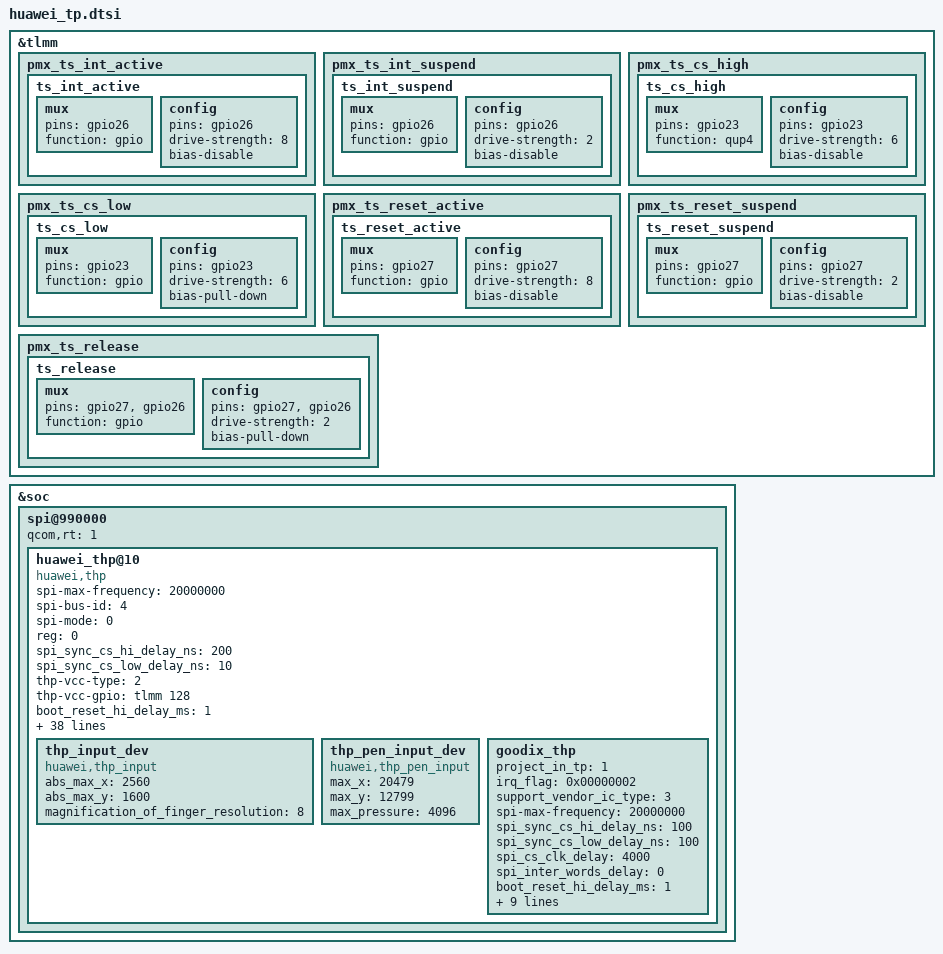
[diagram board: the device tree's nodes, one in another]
/* touch panel config */
&tlmm {
	pmx_ts_int_active {
		ts_int_active: ts_int_active {
			mux {
				pins = "gpio26";
				function = "gpio";
			};

			config {
				pins = "gpio26";
				drive-strength = <8>;
				bias-disable;
			};
		};
	};

	pmx_ts_int_suspend {
		ts_int_suspend: ts_int_suspend {
			mux {
				pins = "gpio26";
				function = "gpio";
			};

			config {
				pins = "gpio26";
				drive-strength = <2>;
				bias-disable;
			};
		};
	};

	pmx_ts_cs_high {
		ts_cs_high: ts_cs_high {
			mux {
				pins = "gpio23";
				function = "qup4";
			};

			config {
				pins = "gpio23";
				drive-strength = <6>;
				bias-disable;
			};
		};
	};

	pmx_ts_cs_low {
		ts_cs_low: ts_cs_low {
			mux {
				pins = "gpio23";
				function = "gpio";
			};

			config {
				pins = "gpio23";
				drive-strength = <6>;
				bias-pull-down;
			};
		};
	};

	pmx_ts_reset_active {
		ts_reset_active: ts_reset_active {
			mux {
				pins = "gpio27";
				function = "gpio";
			};

			config {
				pins = "gpio27";
				drive-strength = <8>;
				bias-disable;
			};
		};
	};

	pmx_ts_reset_suspend {
		ts_reset_suspend: ts_reset_suspend {
			mux {
				pins = "gpio27";
				function = "gpio";
			};

			config {
				pins = "gpio27";
				drive-strength = <2>;
				bias-disable;
			};
		};
	};

	pmx_ts_release {
		ts_release: ts_release {
			mux {
				pins = "gpio27", "gpio26";
				function = "gpio";
			};

			config {
				pins = "gpio27", "gpio26";
				drive-strength = <2>;
				bias-pull-down;
			};
		};
	};
};

&soc {
	spi@990000 {
		status = "ok";
		#address-cells = <1>;
		#size-cells = <0>;
		qcom,rt = <1>;
		huawei_thp@10 {
			compatible = "huawei,thp";
			status = "ok";
			/* SPI Config */
			spi-max-frequency = <20000000>;
			spi-bus-id = <4>;
			spi-mode = <0>;
			reg = <0>;
			spi_sync_cs_hi_delay_ns = <200>;
			spi_sync_cs_low_delay_ns = <10>;

			/* Power Config */
			thp-vcc-type = <2>;
			thp-vcc-gpio = <&tlmm 128 0>;

			/* Timing */
			boot_reset_hi_delay_ms = <1>;
			boot_reset_low_delay_ms = <0>;
			boot_reset_after_delay_ms = <0>;
			resume_reset_after_delay_ms = <1>;
			suspend_reset_after_delay_ms = <1>;
			use_mdelay = <1>;

			/* GPIO Config */
			irq_flag = <0x00000002>;
			interrupt-parent = <&tlmm>;
			interrupts = <26 0>;
			rst_gpio = <&tlmm 27 0x00>;
			irq_gpio = <&tlmm 26 0x00>;
			cs_gpio = <&tlmm 23 0x00>;
			pinctrl-names = "default", "idle", "state_cs_output1", "state_cs_output0";
			pinctrl-0 = <&ts_int_active &ts_reset_active>;
			pinctrl-1 = <&ts_int_suspend &ts_reset_suspend>;
			pinctrl-2 = <&ts_cs_high>;
			pinctrl-3 = <&ts_cs_low>;
			support_no_cs_for_qcom = <1>;
			support_control_cs_off = <1>;

			/* Feature Config */
			support_pinctrl = <1>;
			pinctrl_init_enable = <1>;
			pt_station_test = <0>;
			support_gesture_mode = <1>;
			hide_product_info_en = <1>;
			pen_supported = <1>;
			pen_mt_enable_flag = <1>;
			project_in_tp = <1>;
			support_factory_mode_extra_cmd = <2>;
			need_notify_to_roi_algo = <1>;
			use_thp_queue = <1>;
			supported_charger = <1>;
			need_enable_irq_wake = <1>;
			aptouch_daemon_version = <3>;
			thp_queue_buf_len = <8192>;
			support_dual_chip_arch = <1>;
			send_bt_status_to_fw = <1>;
			send_adsorption_status_to_fw = <1>;
			lcd_esd_event_upload = <1>;
			support_stylus3_plam_suppression = <1>;
			unsupported_stylus = <1>;
			thp_input_dev {
				compatible = "huawei,thp_input";
				abs_max_x = <2560>;
				abs_max_y = <1600>;
				magnification_of_finger_resolution = <8>;
			};
			thp_pen_input_dev {
				compatible = "huawei,thp_pen_input";
				max_x = <20479>;
				max_y = <12799>;
				max_pressure = <4096>;
			};
			goodix_thp {
				status = "ok";
				project_in_tp = <1>;
				irq_flag = <0x00000002>;
				support_vendor_ic_type = <3>;
				spi-max-frequency = <20000000>;
				spi_sync_cs_hi_delay_ns = <100>;
				spi_sync_cs_low_delay_ns = <100>;
				spi_cs_clk_delay = <4000>; // add (spi_cs_clk_delay * 2 / spi_clk) delay
				spi_inter_words_delay = <0>;
				boot_reset_hi_delay_ms = <1>;
				boot_reset_low_delay_ms = <1>;
				boot_reset_after_delay_ms = <100>;
				resume_reset_after_delay_ms = <2>;
				project_id_dummy = "W295AI1500";
				support_dual_chip_arch = <1>;
				support_gesture_mode = <1>;
				need_enable_irq_wake = <1>;
				irq_sync_method = <1>;
				lcd_esd_event_upload = <1>;
			};
		};
	};
};
